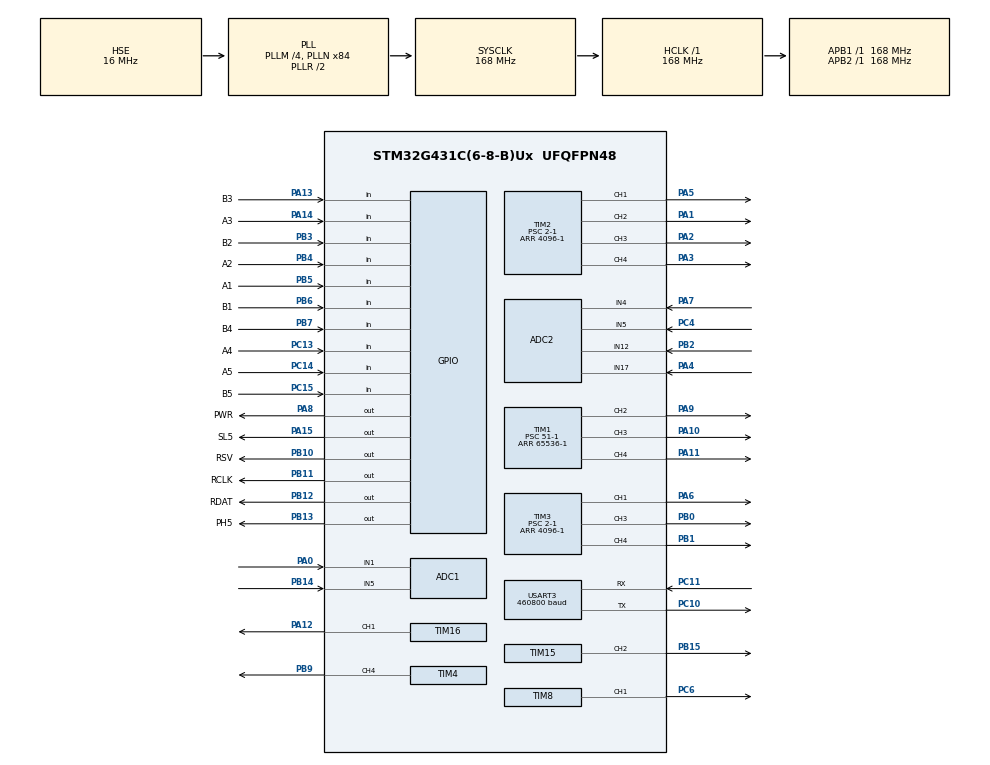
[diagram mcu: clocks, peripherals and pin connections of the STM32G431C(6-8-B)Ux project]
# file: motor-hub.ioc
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ADC1.Channel-1\#ChannelRegularConversion=ADC_CHANNEL_1
ADC1.Channel-2\#ChannelRegularConversion=ADC_CHANNEL_5
ADC1.ContinuousConvMode=ENABLE
ADC1.DMAContinuousRequests=ENABLE
ADC1.EOCSelection=ADC_EOC_SEQ_CONV
ADC1.NbrOfConversion=2
ADC1.NbrOfConversionFlag=1
ADC1.OffsetNumber-1\#ChannelRegularConversion=ADC_OFFSET_NONE
ADC1.OffsetNumber-2\#ChannelRegularConversion=ADC_OFFSET_NONE
ADC1.Overrun=ADC_OVR_DATA_OVERWRITTEN
ADC1.Rank-1\#ChannelRegularConversion=1
ADC1.Rank-2\#ChannelRegularConversion=2
ADC1.SamplingTime-1\#ChannelRegularConversion=ADC_SAMPLETIME_640CYCLES_5
ADC1.SamplingTime-2\#ChannelRegularConversion=ADC_SAMPLETIME_640CYCLES_5
ADC1.master=1
ADC2.Channel-1\#ChannelRegularConversion=ADC_CHANNEL_4
ADC2.Channel-2\#ChannelRegularConversion=ADC_CHANNEL_5
ADC2.Channel-3\#ChannelRegularConversion=ADC_CHANNEL_12
ADC2.Channel-4\#ChannelRegularConversion=ADC_CHANNEL_17
ADC2.ContinuousConvMode=ENABLE
ADC2.DMAContinuousRequests=ENABLE
ADC2.EOCSelection=ADC_EOC_SEQ_CONV
ADC2.NbrOfConversion=4
ADC2.NbrOfConversionFlag=1
ADC2.OffsetNumber-1\#ChannelRegularConversion=ADC_OFFSET_NONE
ADC2.OffsetNumber-2\#ChannelRegularConversion=ADC_OFFSET_NONE
ADC2.OffsetNumber-3\#ChannelRegularConversion=ADC_OFFSET_NONE
ADC2.OffsetNumber-4\#ChannelRegularConversion=ADC_OFFSET_NONE
ADC2.Overrun=ADC_OVR_DATA_OVERWRITTEN
ADC2.Rank-1\#ChannelRegularConversion=1
ADC2.Rank-2\#ChannelRegularConversion=2
ADC2.Rank-3\#ChannelRegularConversion=3
ADC2.Rank-4\#ChannelRegularConversion=4
ADC2.SamplingTime-1\#ChannelRegularConversion=ADC_SAMPLETIME_640CYCLES_5
ADC2.SamplingTime-2\#ChannelRegularConversion=ADC_SAMPLETIME_640CYCLES_5
ADC2.SamplingTime-3\#ChannelRegularConversion=ADC_SAMPLETIME_640CYCLES_5
ADC2.SamplingTime-4\#ChannelRegularConversion=ADC_SAMPLETIME_640CYCLES_5
CRC.CRCLength=CRC_POLYLENGTH_8B
CRC.DefaultInitValueUse=DEFAULT_INIT_VALUE_DISABLE
CRC.DefaultPolynomialUse=DEFAULT_POLYNOMIAL_DISABLE
Dma.ADC1.0.Direction=DMA_PERIPH_TO_MEMORY
Dma.ADC1.0.EventEnable=DISABLE
Dma.ADC1.0.Instance=DMA1_Channel1
Dma.ADC1.0.MemDataAlignment=DMA_MDATAALIGN_HALFWORD
Dma.ADC1.0.MemInc=DMA_MINC_ENABLE
Dma.ADC1.0.Mode=DMA_CIRCULAR
Dma.ADC1.0.PeriphDataAlignment=DMA_PDATAALIGN_HALFWORD
Dma.ADC1.0.PeriphInc=DMA_PINC_DISABLE
Dma.ADC1.0.Polarity=HAL_DMAMUX_REQ_GEN_RISING
Dma.ADC1.0.Priority=DMA_PRIORITY_LOW
Dma.ADC1.0.RequestNumber=1
Dma.ADC1.0.SignalID=NONE
Dma.ADC1.0.SyncEnable=DISABLE
Dma.ADC1.0.SyncPolarity=HAL_DMAMUX_SYNC_NO_EVENT
Dma.ADC1.0.SyncRequestNumber=1
Dma.ADC1.0.SyncSignalID=NONE
Dma.ADC2.1.Direction=DMA_PERIPH_TO_MEMORY
Dma.ADC2.1.EventEnable=DISABLE
Dma.ADC2.1.Instance=DMA1_Channel2
Dma.ADC2.1.MemDataAlignment=DMA_MDATAALIGN_HALFWORD
Dma.ADC2.1.MemInc=DMA_MINC_ENABLE
Dma.ADC2.1.Mode=DMA_CIRCULAR
Dma.ADC2.1.PeriphDataAlignment=DMA_PDATAALIGN_HALFWORD
Dma.ADC2.1.PeriphInc=DMA_PINC_DISABLE
Dma.ADC2.1.Polarity=HAL_DMAMUX_REQ_GEN_RISING
Dma.ADC2.1.Priority=DMA_PRIORITY_LOW
Dma.ADC2.1.RequestNumber=1
Dma.ADC2.1.SignalID=NONE
Dma.ADC2.1.SyncEnable=DISABLE
Dma.ADC2.1.SyncPolarity=HAL_DMAMUX_SYNC_NO_EVENT
Dma.ADC2.1.SyncRequestNumber=1
Dma.ADC2.1.SyncSignalID=NONE
Dma.Request0=ADC1
Dma.Request1=ADC2
Dma.Request2=USART3_RX
Dma.Request3=USART3_TX
Dma.USART3_RX.2.Direction=DMA_PERIPH_TO_MEMORY
Dma.USART3_RX.2.EventEnable=DISABLE
Dma.USART3_RX.2.Instance=DMA2_Channel1
Dma.USART3_RX.2.MemDataAlignment=DMA_MDATAALIGN_BYTE
Dma.USART3_RX.2.MemInc=DMA_MINC_ENABLE
Dma.USART3_RX.2.Mode=DMA_NORMAL
Dma.USART3_RX.2.PeriphDataAlignment=DMA_PDATAALIGN_BYTE
Dma.USART3_RX.2.PeriphInc=DMA_PINC_DISABLE
Dma.USART3_RX.2.Polarity=HAL_DMAMUX_REQ_GEN_RISING
Dma.USART3_RX.2.Priority=DMA_PRIORITY_MEDIUM
Dma.USART3_RX.2.RequestNumber=1
Dma.USART3_RX.2.SignalID=NONE
Dma.USART3_RX.2.SyncEnable=DISABLE
Dma.USART3_RX.2.SyncPolarity=HAL_DMAMUX_SYNC_NO_EVENT
Dma.USART3_RX.2.SyncRequestNumber=1
Dma.USART3_RX.2.SyncSignalID=NONE
Dma.USART3_TX.3.Direction=DMA_MEMORY_TO_PERIPH
Dma.USART3_TX.3.EventEnable=DISABLE
Dma.USART3_TX.3.Instance=DMA1_Channel3
Dma.USART3_TX.3.MemDataAlignment=DMA_MDATAALIGN_BYTE
Dma.USART3_TX.3.MemInc=DMA_MINC_ENABLE
Dma.USART3_TX.3.Mode=DMA_NORMAL
Dma.USART3_TX.3.PeriphDataAlignment=DMA_PDATAALIGN_BYTE
Dma.USART3_TX.3.PeriphInc=DMA_PINC_DISABLE
Dma.USART3_TX.3.Polarity=HAL_DMAMUX_REQ_GEN_RISING
Dma.USART3_TX.3.Priority=DMA_PRIORITY_MEDIUM
Dma.USART3_TX.3.RequestNumber=1
Dma.USART3_TX.3.SignalID=NONE
Dma.USART3_TX.3.SyncEnable=DISABLE
Dma.USART3_TX.3.SyncPolarity=HAL_DMAMUX_SYNC_NO_EVENT
Dma.USART3_TX.3.SyncRequestNumber=1
Dma.USART3_TX.3.SyncSignalID=NONE
Mcu.Family=STM32G4
Mcu.Name=STM32G431C(6-8-B)Ux
Mcu.Package=UFQFPN48
NVIC.DMA1_Channel1_IRQn=true\:0\:0\:false\:false\:true\:false\:true\:true
NVIC.DMA1_Channel2_IRQn=true\:0\:0\:false\:false\:true\:false\:true\:true
NVIC.DMA1_Channel3_IRQn=true\:4\:0\:true\:false\:true\:false\:true\:true
NVIC.DMA2_Channel1_IRQn=true\:4\:0\:true\:false\:true\:false\:true\:true
NVIC.PriorityGroup=NVIC_PRIORITYGROUP_4
NVIC.TIM1_TRG_COM_TIM17_IRQn=true\:2\:0\:true\:false\:true\:true\:true\:true
NVIC.TIM6_DAC_IRQn=true\:3\:0\:true\:false\:true\:true\:true\:true
NVIC.TIM7_IRQn=true\:0\:0\:true\:false\:true\:true\:true\:true
NVIC.USART3_IRQn=true\:1\:0\:true\:false\:true\:true\:true\:true
PA0.Mode=IN1-Single-Ended
PA0.Signal=ADC1_IN1
PA1.Signal=S_TIM2_CH2
PA10.Signal=S_TIM1_CH3
PA11.Signal=S_TIM1_CH4
PA12.Signal=S_TIM16_CH1
PA13.GPIO_Label=B3
PA13.Signal=GPIO_Input
PA14.GPIO_Label=A3
PA14.Signal=GPIO_Input
PA15.GPIO_Label=SL5
PA15.Signal=GPIO_Output
PA2.Signal=S_TIM2_CH3
PA3.Signal=S_TIM2_CH4
PA4.Mode=IN17-Single-Ended
PA4.Signal=ADC2_IN17
PA5.Signal=S_TIM2_CH1
PA6.Signal=S_TIM3_CH1
PA7.Mode=IN4-Single-Ended
PA7.Signal=ADC2_IN4
PA8.GPIO_Label=PWR
PA8.PinState=GPIO_PIN_SET
PA8.Signal=GPIO_Output
PA9.Signal=S_TIM1_CH2
PB0.Signal=S_TIM3_CH3
PB1.Signal=S_TIM3_CH4
PB10.GPIO_Label=RSV
PB10.Signal=GPIO_Output
PB11.GPIO_Label=RCLK
PB11.Signal=GPIO_Output
PB12.GPIO_Label=RDAT
PB12.Signal=GPIO_Output
PB13.GPIO_Label=PH5
PB13.Signal=GPIO_Output
PB14.Mode=IN5-Single-Ended
PB14.Signal=ADC1_IN5
PB15.Signal=S_TIM15_CH2
PB2.Mode=IN12-Single-Ended
PB2.Signal=ADC2_IN12
PB3.GPIO_Label=B2
PB3.Signal=GPIO_Input
PB4.GPIO_Label=A2
PB4.Signal=GPIO_Input
PB5.GPIO_Label=A1
PB5.Signal=GPIO_Input
PB6.GPIO_Label=B1
PB6.Signal=GPIO_Input
PB7.GPIO_Label=B4
PB7.Signal=GPIO_Input
PB9.Signal=S_TIM4_CH4
PC10.Mode=Asynchronous
PC10.Signal=USART3_TX
PC11.Mode=Asynchronous
PC11.Signal=USART3_RX
PC13.GPIO_Label=A4
PC13.Signal=GPIO_Input
PC14-OSC32_IN.GPIO_Label=A5
PC14-OSC32_IN.Signal=GPIO_Input
PC15-OSC32_OUT.GPIO_Label=B5
PC15-OSC32_OUT.Signal=GPIO_Input
PC4.Mode=IN5-Single-Ended
PC4.Signal=ADC2_IN5
PC6.Signal=S_TIM8_CH1
PF0-OSC_IN.Mode=HSE-External-Oscillator
PF0-OSC_IN.Signal=RCC_OSC_IN
PF1-OSC_OUT.Mode=HSE-External-Oscillator
PF1-OSC_OUT.Signal=RCC_OSC_OUT
ProjectManager.HeapSize=0x200
ProjectManager.StackSize=0x400
ProjectManager.TargetToolchain=CMake
RCC.ADC12Freq_Value=168000000
RCC.AHBFreq_Value=168000000
RCC.APB1Freq_Value=168000000
RCC.APB1TimFreq_Value=168000000
RCC.APB2Freq_Value=168000000
RCC.APB2TimFreq_Value=168000000
RCC.CortexFreq_Value=168000000
RCC.EXTERNAL_CLOCK_VALUE=12288000
RCC.HCLKFreq_Value=168000000
RCC.HSE_VALUE=16000000
RCC.HSI48_VALUE=48000000
RCC.HSI_VALUE=16000000
RCC.LSE_VALUE=32768
RCC.PLLM=RCC_PLLM_DIV4
RCC.PLLN=84
RCC.PLLSourceVirtual=RCC_PLLSOURCE_HSE
RCC.SYSCLKFreq_VALUE=168000000
RCC.SYSCLKSource=RCC_SYSCLKSOURCE_PLLCLK
RCC.USBFreq_Value=168000000
RCC.VCOOutputFreq_Value=336000000
SH.S_TIM15_CH2.0=TIM15_CH2,PWM Generation2 CH2
SH.S_TIM16_CH1.0=TIM16_CH1,PWM Generation1 CH1
SH.S_TIM1_CH2.0=TIM1_CH2,PWM Generation2 CH2
SH.S_TIM1_CH3.0=TIM1_CH3,PWM Generation3 CH3
SH.S_TIM1_CH4.0=TIM1_CH4,PWM Generation4 CH4
SH.S_TIM2_CH1.0=TIM2_CH1,PWM Generation1 CH1
SH.S_TIM2_CH2.0=TIM2_CH2,PWM Generation2 CH2
SH.S_TIM2_CH3.0=TIM2_CH3,PWM Generation3 CH3
SH.S_TIM2_CH4.0=TIM2_CH4,PWM Generation4 CH4
SH.S_TIM3_CH1.0=TIM3_CH1,PWM Generation1 CH1
SH.S_TIM3_CH3.0=TIM3_CH3,PWM Generation3 CH3
SH.S_TIM3_CH4.0=TIM3_CH4,PWM Generation4 CH4
SH.S_TIM4_CH4.0=TIM4_CH4,PWM Generation4 CH4
SH.S_TIM8_CH1.0=TIM8_CH1,PWM Generation1 CH1
TIM1.Channel-PWM\ Generation2\ CH2=TIM_CHANNEL_2
TIM1.Channel-PWM\ Generation3\ CH3=TIM_CHANNEL_3
TIM1.Channel-PWM\ Generation4\ CH4=TIM_CHANNEL_4
TIM1.PeriodNoDither=65536-1
TIM1.Prescaler=51-1
TIM15.Channel-PWM\ Generation2\ CH2=TIM_CHANNEL_2
TIM15.PeriodNoDither=4096-1
TIM15.Prescaler=2-1
TIM15.PulseNoDither_2=10
TIM16.Channel=TIM_CHANNEL_1
TIM16.PeriodNoDither=65536-1
TIM16.Prescaler=51-1
TIM17.PeriodNoDither=200-1
TIM17.Prescaler=168-1
TIM2.Channel-PWM\ Generation1\ CH1=TIM_CHANNEL_1
TIM2.Channel-PWM\ Generation2\ CH2=TIM_CHANNEL_2
TIM2.Channel-PWM\ Generation3\ CH3=TIM_CHANNEL_3
TIM2.Channel-PWM\ Generation4\ CH4=TIM_CHANNEL_4
TIM2.PeriodNoDither=4096-1
TIM2.Prescaler=2-1
TIM3.Channel-PWM\ Generation1\ CH1=TIM_CHANNEL_1
TIM3.Channel-PWM\ Generation3\ CH3=TIM_CHANNEL_3
TIM3.Channel-PWM\ Generation4\ CH4=TIM_CHANNEL_4
TIM3.PeriodNoDither=4096-1
TIM3.Prescaler=2-1
TIM4.Channel-PWM\ Generation4\ CH4=TIM_CHANNEL_4
TIM4.PeriodNoDither=4096-1
TIM4.Prescaler=2-1
TIM6.PeriodNoDither=20-1
TIM6.Prescaler=168-1
TIM7.PeriodNoDither=20-1
TIM7.Prescaler=168-1
TIM8.Channel-PWM\ Generation1\ CH1=TIM_CHANNEL_1
TIM8.PeriodNoDither=4096-1
TIM8.Prescaler=2-1
USART3.BaudRate=460800
USART3.Parity=PARITY_NONE
USART3.StopBits=STOPBITS_1
USART3.VirtualMode-Asynchronous=VM_ASYNC
USART3.WordLength=WORDLENGTH_8B
VP_CRC_VS_CRC.Mode=CRC_Activate
VP_SYS_VS_DBSignals.Mode=DisableDeadBatterySignals
VP_TIM15_VS_ClockSourceINT.Mode=Internal
VP_TIM16_VS_ClockSourceINT.Mode=Enable_Timer
VP_TIM17_VS_ClockSourceINT.Mode=Enable_Timer
VP_TIM1_VS_ClockSourceINT.Mode=Internal
VP_TIM2_VS_ClockSourceINT.Mode=Internal
VP_TIM3_VS_ClockSourceINT.Mode=Internal
VP_TIM4_VS_ClockSourceINT.Mode=Internal
VP_TIM6_VS_ClockSourceINT.Mode=Enable_Timer
VP_TIM7_VS_ClockSourceINT.Mode=Enable_Timer
VP_TIM8_VS_ClockSourceINT.Mode=Internal
board=custom

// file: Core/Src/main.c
/* USER CODE BEGIN Header */
/**
  ******************************************************************************
  * @file           : main.c
  * @brief          : Main program body
  ******************************************************************************
  * @attention
  *
  * Copyright (c) 2024 STMicroelectronics.
  * All rights reserved.
  *
  * This software is licensed under terms that can be found in the LICENSE file
  * in the root directory of this software component.
  * If no LICENSE file comes with this software, it is provided AS-IS.
  *
  ******************************************************************************
  */
/* USER CODE END Header */
#include "main.h"

/* USER CODE BEGIN Includes */
#include "app.h"
/* USER CODE END Includes */

ADC_HandleTypeDef hadc1;
ADC_HandleTypeDef hadc2;
DMA_HandleTypeDef hdma_adc1;
DMA_HandleTypeDef hdma_adc2;

CRC_HandleTypeDef hcrc;

TIM_HandleTypeDef htim1;
TIM_HandleTypeDef htim2;
TIM_HandleTypeDef htim3;
TIM_HandleTypeDef htim4;
TIM_HandleTypeDef htim6;
TIM_HandleTypeDef htim7;
TIM_HandleTypeDef htim8;
TIM_HandleTypeDef htim15;
TIM_HandleTypeDef htim16;
TIM_HandleTypeDef htim17;

UART_HandleTypeDef huart3;
DMA_HandleTypeDef hdma_usart3_rx;
DMA_HandleTypeDef hdma_usart3_tx;

void SystemClock_Config(void);
static void MX_GPIO_Init(void);
static void MX_DMA_Init(void);
static void MX_ADC2_Init(void);
static void MX_TIM1_Init(void);
static void MX_TIM2_Init(void);
static void MX_TIM3_Init(void);
static void MX_USART3_UART_Init(void);
static void MX_TIM4_Init(void);
static void MX_ADC1_Init(void);
static void MX_TIM15_Init(void);
static void MX_TIM16_Init(void);
static void MX_TIM6_Init(void);
static void MX_TIM7_Init(void);
static void MX_TIM8_Init(void);
static void MX_CRC_Init(void);
static void MX_TIM17_Init(void);

int main(void)
{

  /* MCU Configuration--------------------------------------------------------*/

  /* Reset of all peripherals, Initializes the Flash interface and the Systick. */
  HAL_Init();

  /* Configure the system clock */
  SystemClock_Config();

  /* Initialize all configured peripherals */
  MX_GPIO_Init();
  MX_DMA_Init();
  MX_ADC2_Init();
  MX_TIM1_Init();
  MX_TIM2_Init();
  MX_TIM3_Init();
  MX_USART3_UART_Init();
  MX_TIM4_Init();
  MX_ADC1_Init();
  MX_TIM15_Init();
  MX_TIM16_Init();
  MX_TIM6_Init();
  MX_TIM7_Init();
  MX_TIM8_Init();
  MX_CRC_Init();
  MX_TIM17_Init();

  /* Infinite loop */
  /* USER CODE BEGIN WHILE */
  App_Init();
  while (1)
  {
    App_Update();
    /* USER CODE END WHILE */

  }
}

void SystemClock_Config(void)
{
  RCC_OscInitTypeDef RCC_OscInitStruct = {0};
  RCC_ClkInitTypeDef RCC_ClkInitStruct = {0};

  /** Configure the main internal regulator output voltage
  */
  HAL_PWREx_ControlVoltageScaling(PWR_REGULATOR_VOLTAGE_SCALE1_BOOST);

  /** Initializes the RCC Oscillators according to the specified parameters
  * in the RCC_OscInitTypeDef structure.
  */
  RCC_OscInitStruct.OscillatorType = RCC_OSCILLATORTYPE_HSE;
  RCC_OscInitStruct.HSEState = RCC_HSE_ON;
  RCC_OscInitStruct.PLL.PLLState = RCC_PLL_ON;
  RCC_OscInitStruct.PLL.PLLSource = RCC_PLLSOURCE_HSE;
  RCC_OscInitStruct.PLL.PLLM = RCC_PLLM_DIV4;
  RCC_OscInitStruct.PLL.PLLN = 84;
  RCC_OscInitStruct.PLL.PLLP = RCC_PLLP_DIV2;
  RCC_OscInitStruct.PLL.PLLQ = RCC_PLLQ_DIV2;
  RCC_OscInitStruct.PLL.PLLR = RCC_PLLR_DIV2;
  if (HAL_RCC_OscConfig(&RCC_OscInitStruct) != HAL_OK)
  {
    Error_Handler();
  }

  /** Initializes the CPU, AHB and APB buses clocks
  */
  RCC_ClkInitStruct.ClockType = RCC_CLOCKTYPE_HCLK|RCC_CLOCKTYPE_SYSCLK
                              |RCC_CLOCKTYPE_PCLK1|RCC_CLOCKTYPE_PCLK2;
  RCC_ClkInitStruct.SYSCLKSource = RCC_SYSCLKSOURCE_PLLCLK;
  RCC_ClkInitStruct.AHBCLKDivider = RCC_SYSCLK_DIV1;
  RCC_ClkInitStruct.APB1CLKDivider = RCC_HCLK_DIV1;
  RCC_ClkInitStruct.APB2CLKDivider = RCC_HCLK_DIV1;

  if (HAL_RCC_ClockConfig(&RCC_ClkInitStruct, FLASH_LATENCY_4) != HAL_OK)
  {
    Error_Handler();
  }
}

static void MX_ADC1_Init(void)
{

  ADC_MultiModeTypeDef multimode = {0};
  ADC_ChannelConfTypeDef sConfig = {0};

  /** Common config
  */
  hadc1.Instance = ADC1;
  hadc1.Init.ClockPrescaler = ADC_CLOCK_SYNC_PCLK_DIV4;
  hadc1.Init.Resolution = ADC_RESOLUTION_12B;
  hadc1.Init.DataAlign = ADC_DATAALIGN_RIGHT;
  hadc1.Init.GainCompensation = 0;
  hadc1.Init.ScanConvMode = ADC_SCAN_ENABLE;
  hadc1.Init.EOCSelection = ADC_EOC_SEQ_CONV;
  hadc1.Init.LowPowerAutoWait = DISABLE;
  hadc1.Init.ContinuousConvMode = ENABLE;
  hadc1.Init.NbrOfConversion = 2;
  hadc1.Init.DiscontinuousConvMode = DISABLE;
  hadc1.Init.ExternalTrigConv = ADC_SOFTWARE_START;
  hadc1.Init.ExternalTrigConvEdge = ADC_EXTERNALTRIGCONVEDGE_NONE;
  hadc1.Init.DMAContinuousRequests = ENABLE;
  hadc1.Init.Overrun = ADC_OVR_DATA_OVERWRITTEN;
  hadc1.Init.OversamplingMode = DISABLE;
  if (HAL_ADC_Init(&hadc1) != HAL_OK)
  {
    Error_Handler();
  }

  /** Configure the ADC multi-mode
  */
  multimode.Mode = ADC_MODE_INDEPENDENT;
  if (HAL_ADCEx_MultiModeConfigChannel(&hadc1, &multimode) != HAL_OK)
  {
    Error_Handler();
  }

  /** Configure Regular Channel
  */
  sConfig.Channel = ADC_CHANNEL_1;
  sConfig.Rank = ADC_REGULAR_RANK_1;
  sConfig.SamplingTime = ADC_SAMPLETIME_640CYCLES_5;
  sConfig.SingleDiff = ADC_SINGLE_ENDED;
  sConfig.OffsetNumber = ADC_OFFSET_NONE;
  sConfig.Offset = 0;
  if (HAL_ADC_ConfigChannel(&hadc1, &sConfig) != HAL_OK)
  {
    Error_Handler();
  }

  /** Configure Regular Channel
  */
  sConfig.Channel = ADC_CHANNEL_5;
  sConfig.Rank = ADC_REGULAR_RANK_2;
  if (HAL_ADC_ConfigChannel(&hadc1, &sConfig) != HAL_OK)
  {
    Error_Handler();
  }

}

static void MX_ADC2_Init(void)
{

  ADC_ChannelConfTypeDef sConfig = {0};

  /** Common config
  */
  hadc2.Instance = ADC2;
  hadc2.Init.ClockPrescaler = ADC_CLOCK_SYNC_PCLK_DIV4;
  hadc2.Init.Resolution = ADC_RESOLUTION_12B;
  hadc2.Init.DataAlign = ADC_DATAALIGN_RIGHT;
  hadc2.Init.GainCompensation = 0;
  hadc2.Init.ScanConvMode = ADC_SCAN_ENABLE;
  hadc2.Init.EOCSelection = ADC_EOC_SEQ_CONV;
  hadc2.Init.LowPowerAutoWait = DISABLE;
  hadc2.Init.ContinuousConvMode = ENABLE;
  hadc2.Init.NbrOfConversion = 4;
  hadc2.Init.DiscontinuousConvMode = DISABLE;
  hadc2.Init.ExternalTrigConv = ADC_SOFTWARE_START;
  hadc2.Init.ExternalTrigConvEdge = ADC_EXTERNALTRIGCONVEDGE_NONE;
  hadc2.Init.DMAContinuousRequests = ENABLE;
  hadc2.Init.Overrun = ADC_OVR_DATA_OVERWRITTEN;
  hadc2.Init.OversamplingMode = DISABLE;
  if (HAL_ADC_Init(&hadc2) != HAL_OK)
  {
    Error_Handler();
  }

  /** Configure Regular Channel
  */
  sConfig.Channel = ADC_CHANNEL_4;
  sConfig.Rank = ADC_REGULAR_RANK_1;
  sConfig.SamplingTime = ADC_SAMPLETIME_640CYCLES_5;
  sConfig.SingleDiff = ADC_SINGLE_ENDED;
  sConfig.OffsetNumber = ADC_OFFSET_NONE;
  sConfig.Offset = 0;
  if (HAL_ADC_ConfigChannel(&hadc2, &sConfig) != HAL_OK)
  {
    Error_Handler();
  }

  /** Configure Regular Channel
  */
  sConfig.Channel = ADC_CHANNEL_5;
  sConfig.Rank = ADC_REGULAR_RANK_2;
  if (HAL_ADC_ConfigChannel(&hadc2, &sConfig) != HAL_OK)
  {
    Error_Handler();
  }

  /** Configure Regular Channel
  */
  sConfig.Channel = ADC_CHANNEL_12;
  sConfig.Rank = ADC_REGULAR_RANK_3;
  if (HAL_ADC_ConfigChannel(&hadc2, &sConfig) != HAL_OK)
  {
    Error_Handler();
  }

  /** Configure Regular Channel
  */
  sConfig.Channel = ADC_CHANNEL_17;
  sConfig.Rank = ADC_REGULAR_RANK_4;
  if (HAL_ADC_ConfigChannel(&hadc2, &sConfig) != HAL_OK)
  {
    Error_Handler();
  }

}

static void MX_CRC_Init(void)
{

  hcrc.Instance = CRC;
  hcrc.Init.DefaultPolynomialUse = DEFAULT_POLYNOMIAL_DISABLE;
  hcrc.Init.DefaultInitValueUse = DEFAULT_INIT_VALUE_DISABLE;
  hcrc.Init.GeneratingPolynomial = 7;
  hcrc.Init.CRCLength = CRC_POLYLENGTH_8B;
  hcrc.Init.InitValue = 0;
  hcrc.Init.InputDataInversionMode = CRC_INPUTDATA_INVERSION_NONE;
  hcrc.Init.OutputDataInversionMode = CRC_OUTPUTDATA_INVERSION_DISABLE;
  hcrc.InputDataFormat = CRC_INPUTDATA_FORMAT_BYTES;
  if (HAL_CRC_Init(&hcrc) != HAL_OK)
  {
    Error_Handler();
  }

}

static void MX_TIM1_Init(void)
{

  TIM_ClockConfigTypeDef sClockSourceConfig = {0};
  TIM_MasterConfigTypeDef sMasterConfig = {0};
  TIM_OC_InitTypeDef sConfigOC = {0};
  TIM_BreakDeadTimeConfigTypeDef sBreakDeadTimeConfig = {0};

  htim1.Instance = TIM1;
  htim1.Init.Prescaler = 51-1;
  htim1.Init.CounterMode = TIM_COUNTERMODE_UP;
  htim1.Init.Period = 65535;
  htim1.Init.ClockDivision = TIM_CLOCKDIVISION_DIV1;
  htim1.Init.RepetitionCounter = 0;
  htim1.Init.AutoReloadPreload = TIM_AUTORELOAD_PRELOAD_DISABLE;
  if (HAL_TIM_Base_Init(&htim1) != HAL_OK)
  {
    Error_Handler();
  }
  sClockSourceConfig.ClockSource = TIM_CLOCKSOURCE_INTERNAL;
  if (HAL_TIM_ConfigClockSource(&htim1, &sClockSourceConfig) != HAL_OK)
  {
    Error_Handler();
  }
  if (HAL_TIM_PWM_Init(&htim1) != HAL_OK)
  {
    Error_Handler();
  }
  sMasterConfig.MasterOutputTrigger = TIM_TRGO_RESET;
  sMasterConfig.MasterOutputTrigger2 = TIM_TRGO2_RESET;
  sMasterConfig.MasterSlaveMode = TIM_MASTERSLAVEMODE_DISABLE;
  if (HAL_TIMEx_MasterConfigSynchronization(&htim1, &sMasterConfig) != HAL_OK)
  {
    Error_Handler();
  }
  sConfigOC.OCMode = TIM_OCMODE_PWM1;
  sConfigOC.Pulse = 0;
  sConfigOC.OCPolarity = TIM_OCPOLARITY_HIGH;
  sConfigOC.OCNPolarity = TIM_OCNPOLARITY_HIGH;
  sConfigOC.OCFastMode = TIM_OCFAST_DISABLE;
  sConfigOC.OCIdleState = TIM_OCIDLESTATE_RESET;
  sConfigOC.OCNIdleState = TIM_OCNIDLESTATE_RESET;
  if (HAL_TIM_PWM_ConfigChannel(&htim1, &sConfigOC, TIM_CHANNEL_2) != HAL_OK)
  {
    Error_Handler();
  }
  if (HAL_TIM_PWM_ConfigChannel(&htim1, &sConfigOC, TIM_CHANNEL_3) != HAL_OK)
  {
    Error_Handler();
  }
  if (HAL_TIM_PWM_ConfigChannel(&htim1, &sConfigOC, TIM_CHANNEL_4) != HAL_OK)
  {
    Error_Handler();
  }
  sBreakDeadTimeConfig.OffStateRunMode = TIM_OSSR_DISABLE;
  sBreakDeadTimeConfig.OffStateIDLEMode = TIM_OSSI_DISABLE;
  sBreakDeadTimeConfig.LockLevel = TIM_LOCKLEVEL_OFF;
  sBreakDeadTimeConfig.DeadTime = 0;
  sBreakDeadTimeConfig.BreakState = TIM_BREAK_DISABLE;
  sBreakDeadTimeConfig.BreakPolarity = TIM_BREAKPOLARITY_HIGH;
  sBreakDeadTimeConfig.BreakFilter = 0;
  sBreakDeadTimeConfig.BreakAFMode = TIM_BREAK_AFMODE_INPUT;
  sBreakDeadTimeConfig.Break2State = TIM_BREAK2_DISABLE;
  sBreakDeadTimeConfig.Break2Polarity = TIM_BREAK2POLARITY_HIGH;
  sBreakDeadTimeConfig.Break2Filter = 0;
  sBreakDeadTimeConfig.Break2AFMode = TIM_BREAK_AFMODE_INPUT;
  sBreakDeadTimeConfig.AutomaticOutput = TIM_AUTOMATICOUTPUT_DISABLE;
  if (HAL_TIMEx_ConfigBreakDeadTime(&htim1, &sBreakDeadTimeConfig) != HAL_OK)
  {
    Error_Handler();
  }
  HAL_TIM_MspPostInit(&htim1);

}

static void MX_TIM2_Init(void)
{

  TIM_ClockConfigTypeDef sClockSourceConfig = {0};
  TIM_MasterConfigTypeDef sMasterConfig = {0};
  TIM_OC_InitTypeDef sConfigOC = {0};

  htim2.Instance = TIM2;
  htim2.Init.Prescaler = 2-1;
  htim2.Init.CounterMode = TIM_COUNTERMODE_UP;
  htim2.Init.Period = 4095;
  htim2.Init.ClockDivision = TIM_CLOCKDIVISION_DIV1;
  htim2.Init.AutoReloadPreload = TIM_AUTORELOAD_PRELOAD_DISABLE;
  if (HAL_TIM_Base_Init(&htim2) != HAL_OK)
  {
    Error_Handler();
  }
  sClockSourceConfig.ClockSource = TIM_CLOCKSOURCE_INTERNAL;
  if (HAL_TIM_ConfigClockSource(&htim2, &sClockSourceConfig) != HAL_OK)
  {
    Error_Handler();
  }
  if (HAL_TIM_PWM_Init(&htim2) != HAL_OK)
  {
    Error_Handler();
  }
  sMasterConfig.MasterOutputTrigger = TIM_TRGO_RESET;
  sMasterConfig.MasterSlaveMode = TIM_MASTERSLAVEMODE_DISABLE;
  if (HAL_TIMEx_MasterConfigSynchronization(&htim2, &sMasterConfig) != HAL_OK)
  {
    Error_Handler();
  }
  sConfigOC.OCMode = TIM_OCMODE_PWM1;
  sConfigOC.Pulse = 0;
  sConfigOC.OCPolarity = TIM_OCPOLARITY_HIGH;
  sConfigOC.OCFastMode = TIM_OCFAST_DISABLE;
  if (HAL_TIM_PWM_ConfigChannel(&htim2, &sConfigOC, TIM_CHANNEL_1) != HAL_OK)
  {
    Error_Handler();
  }
  if (HAL_TIM_PWM_ConfigChannel(&htim2, &sConfigOC, TIM_CHANNEL_2) != HAL_OK)
  {
    Error_Handler();
  }
  if (HAL_TIM_PWM_ConfigChannel(&htim2, &sConfigOC, TIM_CHANNEL_3) != HAL_OK)
  {
    Error_Handler();
  }
  if (HAL_TIM_PWM_ConfigChannel(&htim2, &sConfigOC, TIM_CHANNEL_4) != HAL_OK)
  {
    Error_Handler();
  }
  HAL_TIM_MspPostInit(&htim2);

}

static void MX_TIM3_Init(void)
{

  TIM_ClockConfigTypeDef sClockSourceConfig = {0};
  TIM_MasterConfigTypeDef sMasterConfig = {0};
  TIM_OC_InitTypeDef sConfigOC = {0};

  htim3.Instance = TIM3;
  htim3.Init.Prescaler = 2-1;
  htim3.Init.CounterMode = TIM_COUNTERMODE_UP;
  htim3.Init.Period = 4095;
  htim3.Init.ClockDivision = TIM_CLOCKDIVISION_DIV1;
  htim3.Init.AutoReloadPreload = TIM_AUTORELOAD_PRELOAD_DISABLE;
  if (HAL_TIM_Base_Init(&htim3) != HAL_OK)
  {
    Error_Handler();
  }
  sClockSourceConfig.ClockSource = TIM_CLOCKSOURCE_INTERNAL;
  if (HAL_TIM_ConfigClockSource(&htim3, &sClockSourceConfig) != HAL_OK)
  {
    Error_Handler();
  }
  if (HAL_TIM_PWM_Init(&htim3) != HAL_OK)
  {
    Error_Handler();
  }
  sMasterConfig.MasterOutputTrigger = TIM_TRGO_RESET;
  sMasterConfig.MasterSlaveMode = TIM_MASTERSLAVEMODE_DISABLE;
  if (HAL_TIMEx_MasterConfigSynchronization(&htim3, &sMasterConfig) != HAL_OK)
  {
    Error_Handler();
  }
  sConfigOC.OCMode = TIM_OCMODE_PWM1;
  sConfigOC.Pulse = 0;
  sConfigOC.OCPolarity = TIM_OCPOLARITY_HIGH;
  sConfigOC.OCFastMode = TIM_OCFAST_DISABLE;
  if (HAL_TIM_PWM_ConfigChannel(&htim3, &sConfigOC, TIM_CHANNEL_1) != HAL_OK)
  {
    Error_Handler();
  }
  if (HAL_TIM_PWM_ConfigChannel(&htim3, &sConfigOC, TIM_CHANNEL_3) != HAL_OK)
  {
    Error_Handler();
  }
  if (HAL_TIM_PWM_ConfigChannel(&htim3, &sConfigOC, TIM_CHANNEL_4) != HAL_OK)
  {
    Error_Handler();
  }
  HAL_TIM_MspPostInit(&htim3);

}

static void MX_TIM4_Init(void)
{

  TIM_ClockConfigTypeDef sClockSourceConfig = {0};
  TIM_MasterConfigTypeDef sMasterConfig = {0};
  TIM_OC_InitTypeDef sConfigOC = {0};

  htim4.Instance = TIM4;
  htim4.Init.Prescaler = 2-1;
  htim4.Init.CounterMode = TIM_COUNTERMODE_UP;
  htim4.Init.Period = 4095;
  htim4.Init.ClockDivision = TIM_CLOCKDIVISION_DIV1;
  htim4.Init.AutoReloadPreload = TIM_AUTORELOAD_PRELOAD_DISABLE;
  if (HAL_TIM_Base_Init(&htim4) != HAL_OK)
  {
    Error_Handler();
  }
  sClockSourceConfig.ClockSource = TIM_CLOCKSOURCE_INTERNAL;
  if (HAL_TIM_ConfigClockSource(&htim4, &sClockSourceConfig) != HAL_OK)
  {
    Error_Handler();
  }
  if (HAL_TIM_PWM_Init(&htim4) != HAL_OK)
  {
    Error_Handler();
  }
  sMasterConfig.MasterOutputTrigger = TIM_TRGO_RESET;
  sMasterConfig.MasterSlaveMode = TIM_MASTERSLAVEMODE_DISABLE;
  if (HAL_TIMEx_MasterConfigSynchronization(&htim4, &sMasterConfig) != HAL_OK)
  {
    Error_Handler();
  }
  sConfigOC.OCMode = TIM_OCMODE_PWM1;
  sConfigOC.Pulse = 0;
  sConfigOC.OCPolarity = TIM_OCPOLARITY_HIGH;
  sConfigOC.OCFastMode = TIM_OCFAST_DISABLE;
  if (HAL_TIM_PWM_ConfigChannel(&htim4, &sConfigOC, TIM_CHANNEL_4) != HAL_OK)
  {
    Error_Handler();
  }
  HAL_TIM_MspPostInit(&htim4);

}

static void MX_TIM6_Init(void)
{

  TIM_MasterConfigTypeDef sMasterConfig = {0};

  htim6.Instance = TIM6;
  htim6.Init.Prescaler = 168-1;
  htim6.Init.CounterMode = TIM_COUNTERMODE_UP;
  htim6.Init.Period = 19;
  htim6.Init.AutoReloadPreload = TIM_AUTORELOAD_PRELOAD_DISABLE;
  if (HAL_TIM_Base_Init(&htim6) != HAL_OK)
  {
    Error_Handler();
  }
  sMasterConfig.MasterOutputTrigger = TIM_TRGO_RESET;
  sMasterConfig.MasterSlaveMode = TIM_MASTERSLAVEMODE_DISABLE;
  if (HAL_TIMEx_MasterConfigSynchronization(&htim6, &sMasterConfig) != HAL_OK)
  {
    Error_Handler();
  }

}

static void MX_TIM7_Init(void)
{

  TIM_MasterConfigTypeDef sMasterConfig = {0};

  htim7.Instance = TIM7;
  htim7.Init.Prescaler = 168-1;
  htim7.Init.CounterMode = TIM_COUNTERMODE_UP;
  htim7.Init.Period = 19;
  htim7.Init.AutoReloadPreload = TIM_AUTORELOAD_PRELOAD_DISABLE;
  if (HAL_TIM_Base_Init(&htim7) != HAL_OK)
  {
    Error_Handler();
  }
  sMasterConfig.MasterOutputTrigger = TIM_TRGO_RESET;
  sMasterConfig.MasterSlaveMode = TIM_MASTERSLAVEMODE_DISABLE;
  if (HAL_TIMEx_MasterConfigSynchronization(&htim7, &sMasterConfig) != HAL_OK)
  {
    Error_Handler();
  }

}

static void MX_TIM8_Init(void)
{

  TIM_ClockConfigTypeDef sClockSourceConfig = {0};
  TIM_MasterConfigTypeDef sMasterConfig = {0};
  TIM_OC_InitTypeDef sConfigOC = {0};
  TIM_BreakDeadTimeConfigTypeDef sBreakDeadTimeConfig = {0};

  htim8.Instance = TIM8;
  htim8.Init.Prescaler = 2-1;
  htim8.Init.CounterMode = TIM_COUNTERMODE_UP;
  htim8.Init.Period = 4095;
  htim8.Init.ClockDivision = TIM_CLOCKDIVISION_DIV1;
  htim8.Init.RepetitionCounter = 0;
  htim8.Init.AutoReloadPreload = TIM_AUTORELOAD_PRELOAD_DISABLE;
  if (HAL_TIM_Base_Init(&htim8) != HAL_OK)
  {
    Error_Handler();
  }
  sClockSourceConfig.ClockSource = TIM_CLOCKSOURCE_INTERNAL;
  if (HAL_TIM_ConfigClockSource(&htim8, &sClockSourceConfig) != HAL_OK)
  {
    Error_Handler();
  }
  if (HAL_TIM_PWM_Init(&htim8) != HAL_OK)
  {
    Error_Handler();
  }
  sMasterConfig.MasterOutputTrigger = TIM_TRGO_RESET;
  sMasterConfig.MasterOutputTrigger2 = TIM_TRGO2_RESET;
  sMasterConfig.MasterSlaveMode = TIM_MASTERSLAVEMODE_DISABLE;
  if (HAL_TIMEx_MasterConfigSynchronization(&htim8, &sMasterConfig) != HAL_OK)
  {
    Error_Handler();
  }
  sConfigOC.OCMode = TIM_OCMODE_PWM1;
  sConfigOC.Pulse = 0;
  sConfigOC.OCPolarity = TIM_OCPOLARITY_HIGH;
  sConfigOC.OCNPolarity = TIM_OCNPOLARITY_HIGH;
  sConfigOC.OCFastMode = TIM_OCFAST_DISABLE;
  sConfigOC.OCIdleState = TIM_OCIDLESTATE_RESET;
  sConfigOC.OCNIdleState = TIM_OCNIDLESTATE_RESET;
  if (HAL_TIM_PWM_ConfigChannel(&htim8, &sConfigOC, TIM_CHANNEL_1) != HAL_OK)
  {
    Error_Handler();
  }
  sBreakDeadTimeConfig.OffStateRunMode = TIM_OSSR_DISABLE;
  sBreakDeadTimeConfig.OffStateIDLEMode = TIM_OSSI_DISABLE;
  sBreakDeadTimeConfig.LockLevel = TIM_LOCKLEVEL_OFF;
  sBreakDeadTimeConfig.DeadTime = 0;
  sBreakDeadTimeConfig.BreakState = TIM_BREAK_DISABLE;
  sBreakDeadTimeConfig.BreakPolarity = TIM_BREAKPOLARITY_HIGH;
  sBreakDeadTimeConfig.BreakFilter = 0;
  sBreakDeadTimeConfig.BreakAFMode = TIM_BREAK_AFMODE_INPUT;
  sBreakDeadTimeConfig.Break2State = TIM_BREAK2_DISABLE;
  sBreakDeadTimeConfig.Break2Polarity = TIM_BREAK2POLARITY_HIGH;
  sBreakDeadTimeConfig.Break2Filter = 0;
  sBreakDeadTimeConfig.Break2AFMode = TIM_BREAK_AFMODE_INPUT;
  sBreakDeadTimeConfig.AutomaticOutput = TIM_AUTOMATICOUTPUT_DISABLE;
  if (HAL_TIMEx_ConfigBreakDeadTime(&htim8, &sBreakDeadTimeConfig) != HAL_OK)
  {
    Error_Handler();
  }
  HAL_TIM_MspPostInit(&htim8);

}

static void MX_TIM15_Init(void)
{

  TIM_ClockConfigTypeDef sClockSourceConfig = {0};
  TIM_MasterConfigTypeDef sMasterConfig = {0};
  TIM_OC_InitTypeDef sConfigOC = {0};
  TIM_BreakDeadTimeConfigTypeDef sBreakDeadTimeConfig = {0};

  htim15.Instance = TIM15;
  htim15.Init.Prescaler = 2-1;
  htim15.Init.CounterMode = TIM_COUNTERMODE_UP;
  htim15.Init.Period = 4095;
  htim15.Init.ClockDivision = TIM_CLOCKDIVISION_DIV1;
  htim15.Init.RepetitionCounter = 0;
  htim15.Init.AutoReloadPreload = TIM_AUTORELOAD_PRELOAD_DISABLE;
  if (HAL_TIM_Base_Init(&htim15) != HAL_OK)
  {
    Error_Handler();
  }
  sClockSourceConfig.ClockSource = TIM_CLOCKSOURCE_INTERNAL;
  if (HAL_TIM_ConfigClockSource(&htim15, &sClockSourceConfig) != HAL_OK)
  {
    Error_Handler();
  }
  if (HAL_TIM_PWM_Init(&htim15) != HAL_OK)
  {
    Error_Handler();
  }
  sMasterConfig.MasterOutputTrigger = TIM_TRGO_RESET;
  sMasterConfig.MasterSlaveMode = TIM_MASTERSLAVEMODE_DISABLE;
  if (HAL_TIMEx_MasterConfigSynchronization(&htim15, &sMasterConfig) != HAL_OK)
  {
    Error_Handler();
  }
  sConfigOC.OCMode = TIM_OCMODE_PWM1;
  sConfigOC.Pulse = 10;
  sConfigOC.OCPolarity = TIM_OCPOLARITY_HIGH;
  sConfigOC.OCNPolarity = TIM_OCNPOLARITY_HIGH;
  sConfigOC.OCFastMode = TIM_OCFAST_DISABLE;
  sConfigOC.OCIdleState = TIM_OCIDLESTATE_RESET;
  sConfigOC.OCNIdleState = TIM_OCNIDLESTATE_RESET;
  if (HAL_TIM_PWM_ConfigChannel(&htim15, &sConfigOC, TIM_CHANNEL_2) != HAL_OK)
  {
    Error_Handler();
  }
  sBreakDeadTimeConfig.OffStateRunMode = TIM_OSSR_DISABLE;
  sBreakDeadTimeConfig.OffStateIDLEMode = TIM_OSSI_DISABLE;
  sBreakDeadTimeConfig.LockLevel = TIM_LOCKLEVEL_OFF;
  sBreakDeadTimeConfig.DeadTime = 0;
  sBreakDeadTimeConfig.BreakState = TIM_BREAK_DISABLE;
  sBreakDeadTimeConfig.BreakPolarity = TIM_BREAKPOLARITY_HIGH;
  sBreakDeadTimeConfig.BreakFilter = 0;
  sBreakDeadTimeConfig.AutomaticOutput = TIM_AUTOMATICOUTPUT_DISABLE;
  if (HAL_TIMEx_ConfigBreakDeadTime(&htim15, &sBreakDeadTimeConfig) != HAL_OK)
  {
    Error_Handler();
  }
  HAL_TIM_MspPostInit(&htim15);

}

static void MX_TIM16_Init(void)
{

  TIM_OC_InitTypeDef sConfigOC = {0};
  TIM_BreakDeadTimeConfigTypeDef sBreakDeadTimeConfig = {0};

  htim16.Instance = TIM16;
  htim16.Init.Prescaler = 51-1;
  htim16.Init.CounterMode = TIM_COUNTERMODE_UP;
  htim16.Init.Period = 65535;
  htim16.Init.ClockDivision = TIM_CLOCKDIVISION_DIV1;
  htim16.Init.RepetitionCounter = 0;
  htim16.Init.AutoReloadPreload = TIM_AUTORELOAD_PRELOAD_DISABLE;
  if (HAL_TIM_Base_Init(&htim16) != HAL_OK)
  {
    Error_Handler();
  }
  if (HAL_TIM_PWM_Init(&htim16) != HAL_OK)
  {
    Error_Handler();
  }
  sConfigOC.OCMode = TIM_OCMODE_PWM1;
  sConfigOC.Pulse = 0;
  sConfigOC.OCPolarity = TIM_OCPOLARITY_HIGH;
  sConfigOC.OCNPolarity = TIM_OCNPOLARITY_HIGH;
  sConfigOC.OCFastMode = TIM_OCFAST_DISABLE;
  sConfigOC.OCIdleState = TIM_OCIDLESTATE_RESET;
  sConfigOC.OCNIdleState = TIM_OCNIDLESTATE_RESET;
  if (HAL_TIM_PWM_ConfigChannel(&htim16, &sConfigOC, TIM_CHANNEL_1) != HAL_OK)
  {
    Error_Handler();
  }
  sBreakDeadTimeConfig.OffStateRunMode = TIM_OSSR_DISABLE;
  sBreakDeadTimeConfig.OffStateIDLEMode = TIM_OSSI_DISABLE;
  sBreakDeadTimeConfig.LockLevel = TIM_LOCKLEVEL_OFF;
  sBreakDeadTimeConfig.DeadTime = 0;
  sBreakDeadTimeConfig.BreakState = TIM_BREAK_DISABLE;
  sBreakDeadTimeConfig.BreakPolarity = TIM_BREAKPOLARITY_HIGH;
  sBreakDeadTimeConfig.BreakFilter = 0;
  sBreakDeadTimeConfig.AutomaticOutput = TIM_AUTOMATICOUTPUT_DISABLE;
  if (HAL_TIMEx_ConfigBreakDeadTime(&htim16, &sBreakDeadTimeConfig) != HAL_OK)
  {
    Error_Handler();
  }
  HAL_TIM_MspPostInit(&htim16);

}

static void MX_TIM17_Init(void)
{

  htim17.Instance = TIM17;
  htim17.Init.Prescaler = 168-1;
  htim17.Init.CounterMode = TIM_COUNTERMODE_UP;
  htim17.Init.Period = 199;
  htim17.Init.ClockDivision = TIM_CLOCKDIVISION_DIV1;
  htim17.Init.RepetitionCounter = 0;
  htim17.Init.AutoReloadPreload = TIM_AUTORELOAD_PRELOAD_DISABLE;
  if (HAL_TIM_Base_Init(&htim17) != HAL_OK)
  {
    Error_Handler();
  }

}

static void MX_USART3_UART_Init(void)
{

  huart3.Instance = USART3;
  huart3.Init.BaudRate = 460800;
  huart3.Init.WordLength = UART_WORDLENGTH_8B;
  huart3.Init.StopBits = UART_STOPBITS_1;
  huart3.Init.Parity = UART_PARITY_NONE;
  huart3.Init.Mode = UART_MODE_TX_RX;
  huart3.Init.HwFlowCtl = UART_HWCONTROL_NONE;
  huart3.Init.OverSampling = UART_OVERSAMPLING_16;
  huart3.Init.OneBitSampling = UART_ONE_BIT_SAMPLE_DISABLE;
  huart3.Init.ClockPrescaler = UART_PRESCALER_DIV1;
  huart3.AdvancedInit.AdvFeatureInit = UART_ADVFEATURE_NO_INIT;
  if (HAL_UART_Init(&huart3) != HAL_OK)
  {
    Error_Handler();
  }
  if (HAL_UARTEx_SetTxFifoThreshold(&huart3, UART_TXFIFO_THRESHOLD_1_8) != HAL_OK)
  {
    Error_Handler();
  }
  if (HAL_UARTEx_SetRxFifoThreshold(&huart3, UART_RXFIFO_THRESHOLD_1_8) != HAL_OK)
  {
    Error_Handler();
  }
  if (HAL_UARTEx_DisableFifoMode(&huart3) != HAL_OK)
  {
    Error_Handler();
  }

}

static void MX_DMA_Init(void)
{

  /* DMA controller clock enable */
  __HAL_RCC_DMAMUX1_CLK_ENABLE();
  __HAL_RCC_DMA1_CLK_ENABLE();
  __HAL_RCC_DMA2_CLK_ENABLE();

  /* DMA interrupt init */
  /* DMA1_Channel1_IRQn interrupt configuration */
  HAL_NVIC_SetPriority(DMA1_Channel1_IRQn, 0, 0);
  HAL_NVIC_EnableIRQ(DMA1_Channel1_IRQn);
  /* DMA1_Channel2_IRQn interrupt configuration */
  HAL_NVIC_SetPriority(DMA1_Channel2_IRQn, 0, 0);
  HAL_NVIC_EnableIRQ(DMA1_Channel2_IRQn);
  /* DMA1_Channel3_IRQn interrupt configuration */
  HAL_NVIC_SetPriority(DMA1_Channel3_IRQn, 4, 0);
  HAL_NVIC_EnableIRQ(DMA1_Channel3_IRQn);
  /* DMA2_Channel1_IRQn interrupt configuration */
  HAL_NVIC_SetPriority(DMA2_Channel1_IRQn, 4, 0);
  HAL_NVIC_EnableIRQ(DMA2_Channel1_IRQn);

}

static void MX_GPIO_Init(void)
{
  GPIO_InitTypeDef GPIO_InitStruct = {0};

  /* GPIO Ports Clock Enable */
  __HAL_RCC_GPIOC_CLK_ENABLE();
  __HAL_RCC_GPIOF_CLK_ENABLE();
  __HAL_RCC_GPIOA_CLK_ENABLE();
  __HAL_RCC_GPIOB_CLK_ENABLE();

  /*Configure GPIO pin Output Level */
  HAL_GPIO_WritePin(GPIOB, RSV_Pin|RCLK_Pin|RDAT_Pin|PH5_Pin, GPIO_PIN_RESET);

  /*Configure GPIO pin Output Level */
  HAL_GPIO_WritePin(PWR_GPIO_Port, PWR_Pin, GPIO_PIN_SET);

  /*Configure GPIO pin Output Level */
  HAL_GPIO_WritePin(SL5_GPIO_Port, SL5_Pin, GPIO_PIN_RESET);

  /*Configure GPIO pins : A4_Pin A5_Pin B5_Pin */
  GPIO_InitStruct.Pin = A4_Pin|A5_Pin|B5_Pin;
  GPIO_InitStruct.Mode = GPIO_MODE_INPUT;
  GPIO_InitStruct.Pull = GPIO_NOPULL;
  HAL_GPIO_Init(GPIOC, &GPIO_InitStruct);

  /*Configure GPIO pins : RSV_Pin RCLK_Pin RDAT_Pin PH5_Pin */
  GPIO_InitStruct.Pin = RSV_Pin|RCLK_Pin|RDAT_Pin|PH5_Pin;
  GPIO_InitStruct.Mode = GPIO_MODE_OUTPUT_PP;
  GPIO_InitStruct.Pull = GPIO_NOPULL;
  GPIO_InitStruct.Speed = GPIO_SPEED_FREQ_LOW;
  HAL_GPIO_Init(GPIOB, &GPIO_InitStruct);

  /*Configure GPIO pins : PWR_Pin SL5_Pin */
  GPIO_InitStruct.Pin = PWR_Pin|SL5_Pin;
  GPIO_InitStruct.Mode = GPIO_MODE_OUTPUT_PP;
  GPIO_InitStruct.Pull = GPIO_NOPULL;
  GPIO_InitStruct.Speed = GPIO_SPEED_FREQ_LOW;
  HAL_GPIO_Init(GPIOA, &GPIO_InitStruct);

  /*Configure GPIO pins : B3_Pin A3_Pin */
  GPIO_InitStruct.Pin = B3_Pin|A3_Pin;
  GPIO_InitStruct.Mode = GPIO_MODE_INPUT;
  GPIO_InitStruct.Pull = GPIO_NOPULL;
  HAL_GPIO_Init(GPIOA, &GPIO_InitStruct);

  /*Configure GPIO pins : B2_Pin A2_Pin A1_Pin B1_Pin
                           B4_Pin */
  GPIO_InitStruct.Pin = B2_Pin|A2_Pin|A1_Pin|B1_Pin
                          |B4_Pin;
  GPIO_InitStruct.Mode = GPIO_MODE_INPUT;
  GPIO_InitStruct.Pull = GPIO_NOPULL;
  HAL_GPIO_Init(GPIOB, &GPIO_InitStruct);

}

void Error_Handler(void)
{
  __disable_irq();
  while (1)
  {
  }
}
